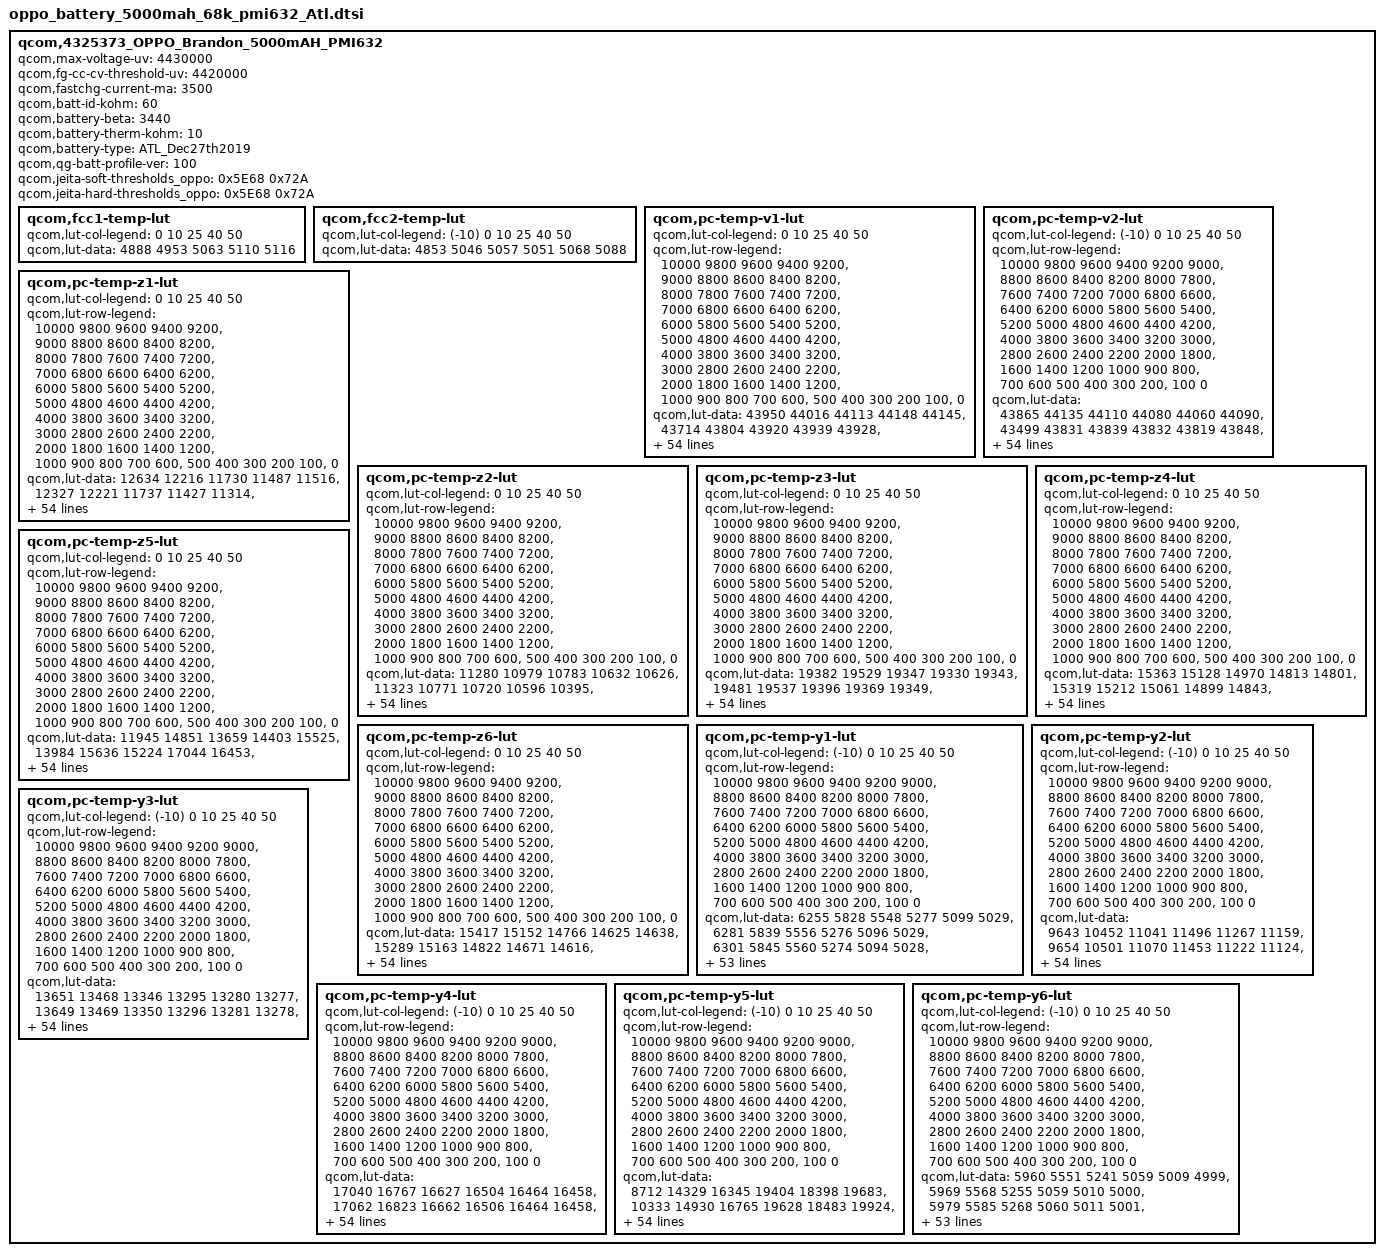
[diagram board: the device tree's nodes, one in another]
qcom,4325373_OPPO_Brandon_5000mAH_PMI632 {
    /* 4325373_OPPO_Brandon_5000mAH_PMI632_averaged_MasterSlave_Dec27th2019 */
    qcom,max-voltage-uv = <4430000>;
    qcom,fg-cc-cv-threshold-uv = <4420000>;
    qcom,fastchg-current-ma = <3500>;
    qcom,batt-id-kohm = <60>;
    qcom,battery-beta = <3440>;
    qcom,battery-therm-kohm = <10>;
    qcom,battery-type = "ATL_Dec27th2019";
    qcom,qg-batt-profile-ver = <100>;
    qcom,jeita-soft-thresholds_oppo = <0x5E68 0x72A>;
    qcom,jeita-hard-thresholds_oppo = <0x5E68 0x72A>;

	qcom,fcc1-temp-lut {
		qcom,lut-col-legend = <0 10 25 40 50>;
		qcom,lut-data = <4888 4953 5063 5110 5116>;
	};

	qcom,fcc2-temp-lut {
		qcom,lut-col-legend = <(-10) 0 10 25 40 50>;
		qcom,lut-data = <4853 5046 5057 5051 5068 5088>;
	};

	qcom,pc-temp-v1-lut {
		qcom,lut-col-legend = <0 10 25 40 50>;
		qcom,lut-row-legend = <10000 9800 9600 9400 9200>,
			<9000 8800 8600 8400 8200>,
			<8000 7800 7600 7400 7200>,
			<7000 6800 6600 6400 6200>,
			<6000 5800 5600 5400 5200>,
			<5000 4800 4600 4400 4200>,
			<4000 3800 3600 3400 3200>,
			<3000 2800 2600 2400 2200>,
			<2000 1800 1600 1400 1200>,
			<1000 900 800 700 600>,
			<500 400 300 200 100>,
			<0>;
		qcom,lut-data = <43950 44016 44113 44148 44145>,
			<43714 43804 43920 43939 43928>,
			<43479 43585 43722 43740 43733>,
			<43250 43361 43516 43537 43527>,
			<43023 43131 43290 43324 43313>,
			<42789 42897 43052 43103 43091>,
			<42550 42657 42813 42873 42861>,
			<42313 42418 42573 42635 42625>,
			<42082 42182 42333 42391 42384>,
			<41855 41947 42093 42151 42146>,
			<41630 41719 41855 41915 41913>,
			<41409 41495 41625 41682 41681>,
			<41194 41277 41402 41452 41453>,
			<40990 41069 41184 41227 41227>,
			<40791 40866 40970 41010 41008>,
			<40593 40666 40763 40802 40796>,
			<40401 40466 40564 40601 40592>,
			<40221 40276 40373 40409 40397>,
			<40057 40110 40188 40223 40211>,
			<39896 39959 40021 40047 40037>,
			<39713 39775 39850 39877 39873>,
			<39482 39524 39617 39673 39676>,
			<39260 39272 39312 39393 39405>,
			<39080 39077 39088 39146 39160>,
			<38926 38909 38964 39001 39014>,
			<38800 38787 38868 38891 38904>,
			<38684 38704 38770 38782 38791>,
			<38588 38636 38678 38676 38677>,
			<38511 38565 38590 38578 38571>,
			<38442 38496 38504 38483 38476>,
			<38376 38433 38424 38396 38389>,
			<38312 38373 38353 38320 38311>,
			<38256 38319 38290 38252 38240>,
			<38207 38271 38233 38187 38172>,
			<38164 38228 38185 38126 38104>,
			<38118 38188 38139 38066 38037>,
			<38058 38153 38092 38008 37969>,
			<38004 38115 38043 37953 37901>,
			<37976 38053 37978 37884 37821>,
			<37957 37955 37886 37789 37721>,
			<37917 37843 37777 37679 37608>,
			<37798 37719 37661 37562 37487>,
			<37643 37578 37526 37431 37352>,
			<37474 37410 37357 37271 37193>,
			<37342 37253 37204 37127 37058>,
			<37230 37153 37103 37039 36979>,
			<37188 37121 37074 37011 36950>,
			<37153 37095 37053 36991 36933>,
			<37125 37080 37031 36972 36911>,
			<37077 37032 36986 36911 36837>,
			<36914 36818 36751 36643 36547>,
			<36490 36378 36318 36201 36104>,
			<35919 35797 35745 35626 35528>,
			<35130 35000 34966 34841 34741>,
			<33816 33717 33765 33619 33516>,
			<30000 30000 30000 30000 30000>;
	};

	qcom,pc-temp-v2-lut {
		qcom,lut-col-legend = <(-10) 0 10 25 40 50>;
		qcom,lut-row-legend = <10000 9800 9600 9400 9200 9000>,
			<8800 8600 8400 8200 8000 7800>,
			<7600 7400 7200 7000 6800 6600>,
			<6400 6200 6000 5800 5600 5400>,
			<5200 5000 4800 4600 4400 4200>,
			<4000 3800 3600 3400 3200 3000>,
			<2800 2600 2400 2200 2000 1800>,
			<1600 1400 1200 1000 900 800>,
			<700 600 500 400 300 200>,
			<100 0>;
		qcom,lut-data = <43865 44135 44110 44080 44060 44090>,
			<43499 43831 43839 43832 43819 43848>,
			<43166 43548 43580 43591 43584 43614>,
			<42874 43290 43337 43357 43356 43386>,
			<42622 43056 43110 43133 43134 43168>,
			<42374 42822 42880 42905 42908 42944>,
			<42100 42578 42639 42667 42672 42710>,
			<41820 42333 42395 42426 42433 42471>,
			<41568 42090 42152 42186 42195 42233>,
			<41345 41850 41909 41948 41956 41993>,
			<41172 41606 41671 41713 41722 41757>,
			<41034 41335 41439 41483 41490 41525>,
			<40867 41080 41213 41258 41264 41297>,
			<40636 40908 40996 41038 41045 41074>,
			<40272 40786 40785 40823 40831 40856>,
			<39919 40630 40579 40616 40624 40647>,
			<39674 40369 40381 40416 40422 40446>,
			<39471 40067 40181 40223 40228 40253>,
			<39272 39810 39964 40041 40048 40073>,
			<39068 39573 39731 39867 39877 39899>,
			<38872 39342 39500 39668 39678 39697>,
			<38694 39114 39264 39408 39420 39448>,
			<38546 38896 39044 39151 39170 39209>,
			<38435 38692 38862 38961 38985 39020>,
			<38349 38497 38703 38803 38829 38857>,
			<38276 38351 38560 38666 38694 38717>,
			<38211 38236 38433 38545 38576 38596>,
			<38151 38145 38316 38437 38469 38488>,
			<38093 38081 38197 38337 38372 38387>,
			<38037 38030 38084 38243 38282 38293>,
			<37982 37983 38002 38158 38201 38208>,
			<37924 37939 37938 38080 38127 38131>,
			<37865 37895 37886 38007 38055 38057>,
			<37804 37846 37844 37939 37983 37985>,
			<37743 37795 37808 37874 37908 37909>,
			<37679 37741 37767 37804 37821 37813>,
			<37611 37684 37721 37730 37720 37694>,
			<37540 37620 37666 37652 37618 37581>,
			<37460 37546 37598 37574 37523 37484>,
			<37374 37462 37515 37493 37431 37390>,
			<37285 37367 37413 37405 37340 37299>,
			<37192 37257 37284 37309 37251 37207>,
			<37099 37133 37142 37192 37134 37086>,
			<37014 36992 36990 37050 36996 36948>,
			<36935 36846 36846 36920 36890 36835>,
			<36856 36754 36755 36865 36846 36798>,
			<36814 36723 36722 36846 36831 36787>,
			<36762 36698 36683 36829 36816 36771>,
			<36688 36658 36637 36794 36792 36740>,
			<36577 36599 36545 36731 36701 36643>,
			<36382 36433 36330 36490 36398 36310>,
			<36035 36015 35883 36018 35896 35810>,
			<35377 35356 35252 35400 35252 35158>,
			<34603 34363 34370 34554 34366 34257>,
			<33605 32848 32889 33221 32988 32849>,
			<30247 29719 28617 28832 28080 28127>;
	};

	qcom,pc-temp-z1-lut {
		qcom,lut-col-legend = <0 10 25 40 50>;
		qcom,lut-row-legend = <10000 9800 9600 9400 9200>,
			<9000 8800 8600 8400 8200>,
			<8000 7800 7600 7400 7200>,
			<7000 6800 6600 6400 6200>,
			<6000 5800 5600 5400 5200>,
			<5000 4800 4600 4400 4200>,
			<4000 3800 3600 3400 3200>,
			<3000 2800 2600 2400 2200>,
			<2000 1800 1600 1400 1200>,
			<1000 900 800 700 600>,
			<500 400 300 200 100>,
			<0>;
		qcom,lut-data = <12634 12216 11730 11487 11516>,
			<12327 12221 11737 11427 11314>,
			<12199 12222 11733 11424 11315>,
			<12193 12216 11727 11420 11313>,
			<12187 12202 11717 11415 11310>,
			<12177 12192 11702 11408 11307>,
			<12164 12184 11691 11401 11304>,
			<12153 12175 11683 11395 11302>,
			<12144 12163 11676 11391 11300>,
			<12135 12147 11669 11389 11299>,
			<12126 12134 11663 11387 11299>,
			<12119 12124 11658 11386 11299>,
			<12113 12117 11653 11385 11299>,
			<12108 12115 11651 11385 11299>,
			<12103 12114 11653 11385 11299>,
			<12095 12112 11656 11386 11300>,
			<12088 12112 11658 11387 11301>,
			<12089 12113 11659 11388 11303>,
			<12099 12113 11659 11389 11304>,
			<12107 12112 11660 11390 11306>,
			<12102 12112 11661 11392 11307>,
			<12090 12113 11663 11393 11308>,
			<12089 12115 11666 11394 11310>,
			<12104 12120 11669 11396 11312>,
			<12118 12131 11673 11398 11314>,
			<12118 12135 11677 11402 11317>,
			<12111 12134 11681 11406 11320>,
			<12109 12133 11685 11410 11323>,
			<12116 12136 11690 11414 11326>,
			<12125 12145 11695 11418 11330>,
			<12127 12151 11699 11422 11334>,
			<12125 12154 11703 11427 11338>,
			<12125 12157 11706 11431 11341>,
			<12126 12158 11711 11435 11344>,
			<12129 12161 11719 11439 11349>,
			<12143 12164 11727 11444 11353>,
			<12391 12169 11729 11448 11356>,
			<12682 12177 11732 11452 11360>,
			<12746 12190 11735 11457 11363>,
			<12777 12214 11743 11461 11366>,
			<12795 12225 11752 11466 11370>,
			<12799 12219 11761 11470 11373>,
			<12798 12213 11769 11474 11377>,
			<12817 12225 11775 11479 11380>,
			<12813 12241 11782 11486 11384>,
			<12831 12244 11792 11490 11386>,
			<12842 12234 11791 11491 11386>,
			<12829 12232 11795 11493 11387>,
			<12830 12249 11804 11495 11389>,
			<12836 12244 11804 11502 11393>,
			<12846 12253 11813 11508 11398>,
			<12845 12276 11828 11515 11404>,
			<12865 12294 11827 11525 11413>,
			<12893 12322 11859 11540 11427>,
			<12893 12322 11859 11540 11427>,
			<12893 12322 11859 11540 11427>;
	};

	qcom,pc-temp-z2-lut {
		qcom,lut-col-legend = <0 10 25 40 50>;
		qcom,lut-row-legend = <10000 9800 9600 9400 9200>,
			<9000 8800 8600 8400 8200>,
			<8000 7800 7600 7400 7200>,
			<7000 6800 6600 6400 6200>,
			<6000 5800 5600 5400 5200>,
			<5000 4800 4600 4400 4200>,
			<4000 3800 3600 3400 3200>,
			<3000 2800 2600 2400 2200>,
			<2000 1800 1600 1400 1200>,
			<1000 900 800 700 600>,
			<500 400 300 200 100>,
			<0>;
		qcom,lut-data = <11280 10979 10783 10632 10626>,
			<11323 10771 10720 10596 10395>,
			<11347 10646 11165 10622 10424>,
			<11232 10609 11499 10626 10509>,
			<11036 10570 11255 10686 10533>,
			<10831 10537 10771 11009 10501>,
			<10580 10507 10615 11198 10466>,
			<10455 10484 10582 10904 10442>,
			<10568 10467 10559 10499 10420>,
			<10745 10453 10537 10529 10395>,
			<10746 10450 10521 10892 10367>,
			<10583 10451 10557 11116 10335>,
			<10477 10455 10774 11174 10286>,
			<10584 10470 10942 11205 10243>,
			<10765 10503 10991 11194 10253>,
			<10840 10528 11022 11157 10300>,
			<10874 10544 10977 11142 10325>,
			<10908 10560 10751 11172 10338>,
			<10881 10581 10626 11200 10352>,
			<10736 10605 10633 11004 10362>,
			<10662 10624 10642 10557 10372>,
			<10633 10641 10666 10446 10386>,
			<10629 10652 10715 10544 10431>,
			<10612 10643 10738 10619 10476>,
			<10580 10615 10689 10578 10491>,
			<10574 10602 10630 10492 10514>,
			<10615 10602 10638 10494 10567>,
			<10653 10604 10683 10648 10728>,
			<10653 10607 10712 10753 10837>,
			<10642 10613 10723 10730 10736>,
			<10635 10620 10729 10682 10542>,
			<10632 10628 10724 10635 10417>,
			<10632 10636 10709 10576 10318>,
			<10641 10645 10703 10550 10278>,
			<10664 10653 10705 10561 10306>,
			<10674 10662 10710 10584 10356>,
			<10616 10670 10725 10612 10406>,
			<10551 10680 10757 10654 10464>,
			<10561 10693 10783 10694 10512>,
			<10605 10712 10803 10743 10553>,
			<10639 10726 10818 10779 10589>,
			<10655 10732 10825 10787 10617>,
			<10678 10741 10830 10790 10642>,
			<10738 10767 10844 10773 10690>,
			<10726 10941 10902 10750 10675>,
			<10580 11064 10944 10676 10571>,
			<10518 11071 10930 10664 10558>,
			<10463 11076 10903 10665 10579>,
			<10187 11441 10904 10683 10604>,
			<10491 11449 10973 10781 10672>,
			<10208 11419 11026 10654 10506>,
			<10095 11276 10973 10490 10321>,
			<9865 11099 10906 10443 10266>,
			<9689 10844 10893 10386 10202>,
			<9689 10844 10893 10386 10202>,
			<9689 10844 10893 10386 10202>;
	};

	qcom,pc-temp-z3-lut {
		qcom,lut-col-legend = <0 10 25 40 50>;
		qcom,lut-row-legend = <10000 9800 9600 9400 9200>,
			<9000 8800 8600 8400 8200>,
			<8000 7800 7600 7400 7200>,
			<7000 6800 6600 6400 6200>,
			<6000 5800 5600 5400 5200>,
			<5000 4800 4600 4400 4200>,
			<4000 3800 3600 3400 3200>,
			<3000 2800 2600 2400 2200>,
			<2000 1800 1600 1400 1200>,
			<1000 900 800 700 600>,
			<500 400 300 200 100>,
			<0>;
		qcom,lut-data = <19382 19529 19347 19330 19343>,
			<19481 19537 19396 19369 19349>,
			<19544 19546 19413 19387 19362>,
			<19582 19558 19425 19397 19378>,
			<19600 19572 19441 19406 19387>,
			<19606 19578 19456 19416 19392>,
			<19604 19581 19460 19421 19397>,
			<19601 19582 19459 19417 19401>,
			<19607 19580 19457 19412 19404>,
			<19616 19576 19457 19413 19403>,
			<19610 19571 19455 19420 19396>,
			<19589 19567 19455 19422 19389>,
			<19575 19563 19455 19418 19385>,
			<19574 19556 19454 19413 19381>,
			<19577 19547 19451 19407 19378>,
			<19579 19541 19447 19400 19376>,
			<19577 19538 19440 19394 19374>,
			<19574 19535 19426 19390 19370>,
			<19564 19528 19418 19386 19367>,
			<19550 19519 19417 19378 19361>,
			<19542 19518 19416 19366 19355>,
			<19542 19539 19419 19364 19352>,
			<19547 19560 19432 19368 19353>,
			<19552 19559 19439 19372 19353>,
			<19550 19552 19425 19364 19347>,
			<19546 19544 19409 19349 19334>,
			<19545 19537 19408 19348 19336>,
			<19544 19532 19410 19363 19375>,
			<19542 19531 19413 19379 19402>,
			<19542 19533 19427 19391 19400>,
			<19541 19535 19439 19401 19395>,
			<19540 19537 19440 19402 19389>,
			<19538 19538 19440 19395 19380>,
			<19534 19538 19440 19389 19371>,
			<19528 19536 19435 19383 19363>,
			<19525 19534 19429 19378 19357>,
			<19551 19531 19426 19373 19353>,
			<19588 19526 19424 19368 19351>,
			<19609 19522 19421 19365 19349>,
			<19625 19518 19418 19363 19346>,
			<19629 19514 19415 19362 19344>,
			<19621 19510 19411 19363 19347>,
			<19609 19504 19406 19364 19354>,
			<19589 19493 19404 19364 19359>,
			<19378 19462 19394 19360 19357>,
			<19289 19433 19382 19347 19340>,
			<19286 19427 19380 19344 19338>,
			<19283 19423 19377 19343 19328>,
			<19264 19319 19377 19336 19324>,
			<19278 19316 19363 19329 19323>,
			<19263 19322 19359 19352 19351>,
			<19264 19312 19370 19364 19358>,
			<19266 19310 19375 19362 19356>,
			<19272 19311 19357 19355 19354>,
			<19272 19311 19357 19355 19354>,
			<19272 19311 19357 19355 19354>;
	};

	qcom,pc-temp-z4-lut {
		qcom,lut-col-legend = <0 10 25 40 50>;
		qcom,lut-row-legend = <10000 9800 9600 9400 9200>,
			<9000 8800 8600 8400 8200>,
			<8000 7800 7600 7400 7200>,
			<7000 6800 6600 6400 6200>,
			<6000 5800 5600 5400 5200>,
			<5000 4800 4600 4400 4200>,
			<4000 3800 3600 3400 3200>,
			<3000 2800 2600 2400 2200>,
			<2000 1800 1600 1400 1200>,
			<1000 900 800 700 600>,
			<500 400 300 200 100>,
			<0>;
		qcom,lut-data = <15363 15128 14970 14813 14801>,
			<15319 15212 15061 14899 14843>,
			<15237 15232 15019 14893 14844>,
			<15129 15172 14964 14862 14825>,
			<15048 15070 14922 14829 14806>,
			<14992 14995 14882 14790 14786>,
			<14947 14939 14848 14764 14767>,
			<14910 14894 14819 14755 14749>,
			<14861 14859 14793 14747 14732>,
			<14813 14830 14770 14732 14720>,
			<14794 14806 14749 14699 14711>,
			<14790 14785 14729 14678 14704>,
			<14784 14768 14706 14672 14700>,
			<14764 14752 14691 14668 14696>,
			<14740 14739 14685 14665 14690>,
			<14727 14735 14680 14663 14685>,
			<14718 14735 14681 14660 14680>,
			<14707 14734 14693 14657 14675>,
			<14695 14730 14699 14654 14673>,
			<14696 14721 14697 14657 14672>,
			<14712 14719 14696 14669 14673>,
			<14749 14744 14715 14688 14679>,
			<14779 14779 14789 14752 14743>,
			<14793 14808 14829 14805 14800>,
			<14806 14836 14832 14812 14803>,
			<14813 14845 14833 14815 14803>,
			<14813 14834 14829 14812 14795>,
			<14804 14816 14810 14783 14742>,
			<14788 14802 14789 14750 14699>,
			<14768 14787 14764 14724 14690>,
			<14754 14774 14742 14703 14684>,
			<14742 14763 14731 14693 14681>,
			<14733 14754 14723 14687 14678>,
			<14727 14748 14720 14685 14677>,
			<14722 14745 14719 14686 14676>,
			<14720 14741 14718 14687 14677>,
			<14793 14737 14718 14689 14677>,
			<14877 14733 14719 14690 14678>,
			<14861 14732 14720 14692 14681>,
			<14777 14732 14725 14702 14692>,
			<14731 14731 14728 14710 14703>,
			<14726 14723 14721 14706 14698>,
			<14721 14712 14708 14696 14688>,
			<14715 14705 14702 14695 14687>,
			<14850 14683 14687 14688 14681>,
			<14913 14676 14666 14671 14666>,
			<14915 14675 14658 14665 14661>,
			<14915 14673 14648 14652 14655>,
			<14927 14782 14637 14640 14637>,
			<14910 14782 14646 14642 14632>,
			<14922 14780 14669 14648 14645>,
			<14938 14802 14663 14649 14650>,
			<14949 14809 14659 14654 14655>,
			<14968 14817 14683 14664 14660>,
			<14968 14817 14683 14664 14660>,
			<14968 14817 14683 14664 14660>;
	};

	qcom,pc-temp-z5-lut {
		qcom,lut-col-legend = <0 10 25 40 50>;
		qcom,lut-row-legend = <10000 9800 9600 9400 9200>,
			<9000 8800 8600 8400 8200>,
			<8000 7800 7600 7400 7200>,
			<7000 6800 6600 6400 6200>,
			<6000 5800 5600 5400 5200>,
			<5000 4800 4600 4400 4200>,
			<4000 3800 3600 3400 3200>,
			<3000 2800 2600 2400 2200>,
			<2000 1800 1600 1400 1200>,
			<1000 900 800 700 600>,
			<500 400 300 200 100>,
			<0>;
		qcom,lut-data = <11945 14851 13659 14403 15525>,
			<13984 15636 15224 17044 16453>,
			<15560 16298 15768 18124 17291>,
			<16791 16846 16164 18758 19113>,
			<17716 17517 17077 19495 20130>,
			<18238 18203 18350 20439 20754>,
			<18617 18924 19087 21008 21472>,
			<19115 19670 19530 21076 22983>,
			<21861 20408 20054 21140 24613>,
			<25425 21166 20982 22512 24885>,
			<25727 22011 22192 27328 24712>,
			<23578 22979 23573 30993 24654>,
			<22304 23993 26399 32938 24936>,
			<24172 25018 28597 34122 25482>,
			<27356 26058 29820 33821 26347>,
			<29658 27031 30935 32639 27861>,
			<31519 28129 30745 32224 29357>,
			<32410 28840 28024 33256 30970>,
			<31113 28652 26755 34357 32120>,
			<28413 28106 27635 32479 31695>,
			<28417 28893 29074 27768 30048>,
			<32974 44785 32092 26609 28410>,
			<37804 60858 38136 27228 26977>,
			<42160 58184 40771 27655 25269>,
			<42372 46674 33389 24650 21814>,
			<39670 38268 24164 18778 17261>,
			<37184 33124 22310 17465 16880>,
			<34845 29989 21661 18378 22317>,
			<32702 29890 21589 19800 26931>,
			<31704 30465 24412 23063 28469>,
			<32307 31366 28687 27294 29511>,
			<33589 33800 32282 29123 29641>,
			<34812 36951 35832 30062 28891>,
			<35394 39471 37804 30968 28497>,
			<35834 41872 38823 32331 28585>,
			<35933 42804 39409 33432 28745>,
			<33140 42524 39584 33192 28981>,
			<30032 42024 39541 31896 29253>,
			<31748 41551 39113 30585 29041>,
			<37693 41024 36797 28758 26588>,
			<40452 40417 34086 27110 24183>,
			<38968 39385 32053 26531 24559>,
			<36883 37946 30707 26210 26081>,
			<34864 35086 30675 26053 28290>,
			<19093 35666 30941 26145 28666>,
			<12486 30485 31479 23454 23003>,
			<12365 27295 31471 23061 22195>,
			<12263 26561 31590 25194 20679>,
			<11900 13457 34347 25746 24095>,
			<12104 13365 26391 22599 24367>,
			<11936 13663 21085 25931 29236>,
			<11854 13029 21833 26048 26618>,
			<11756 12820 22156 23083 22620>,
			<11812 12679 18207 18814 18982>,
			<11812 12679 18207 18814 18982>,
			<11812 12679 18207 18814 18982>;
	};

	qcom,pc-temp-z6-lut {
		qcom,lut-col-legend = <0 10 25 40 50>;
		qcom,lut-row-legend = <10000 9800 9600 9400 9200>,
			<9000 8800 8600 8400 8200>,
			<8000 7800 7600 7400 7200>,
			<7000 6800 6600 6400 6200>,
			<6000 5800 5600 5400 5200>,
			<5000 4800 4600 4400 4200>,
			<4000 3800 3600 3400 3200>,
			<3000 2800 2600 2400 2200>,
			<2000 1800 1600 1400 1200>,
			<1000 900 800 700 600>,
			<500 400 300 200 100>,
			<0>;
		qcom,lut-data = <15417 15152 14766 14625 14638>,
			<15289 15163 14822 14671 14616>,
			<15207 15165 14810 14672 14622>,
			<15158 15139 14793 14665 14623>,
			<15119 15081 14780 14658 14622>,
			<15084 15036 14765 14647 14616>,
			<15051 15003 14751 14637 14609>,
			<15023 14973 14735 14630 14604>,
			<14997 14948 14720 14623 14599>,
			<14974 14925 14707 14615 14592>,
			<14953 14906 14695 14606 14584>,
			<14936 14890 14685 14599 14578>,
			<14921 14876 14675 14594 14573>,
			<14908 14863 14668 14589 14569>,
			<14897 14851 14663 14584 14565>,
			<14888 14845 14659 14579 14562>,
			<14879 14842 14656 14575 14558>,
			<14870 14839 14653 14571 14554>,
			<14860 14834 14652 14568 14551>,
			<14853 14826 14651 14566 14548>,
			<14853 14825 14650 14565 14544>,
			<14870 14848 14660 14567 14546>,
			<14886 14875 14701 14599 14574>,
			<14896 14888 14721 14625 14599>,
			<14903 14897 14717 14624 14598>,
			<14904 14900 14710 14619 14593>,
			<14904 14892 14705 14616 14590>,
			<14902 14883 14700 14612 14587>,
			<14896 14878 14696 14609 14585>,
			<14888 14875 14694 14605 14581>,
			<14883 14872 14691 14602 14577>,
			<14878 14869 14689 14598 14572>,
			<14874 14868 14687 14593 14567>,
			<14870 14867 14685 14589 14562>,
			<14866 14866 14683 14587 14558>,
			<14870 14865 14681 14585 14555>,
			<14994 14865 14681 14584 14554>,
			<15137 14864 14681 14582 14553>,
			<15148 14865 14681 14581 14553>,
			<15132 14867 14683 14585 14557>,
			<15125 14869 14685 14589 14561>,
			<15128 14868 14682 14588 14561>,
			<15130 14866 14677 14585 14561>,
			<15129 14864 14676 14585 14562>,
			<15102 14851 14669 14581 14560>,
			<15086 14837 14657 14568 14545>,
			<15087 14834 14653 14564 14542>,
			<15086 14832 14648 14558 14534>,
			<15084 14828 14644 14549 14524>,
			<15088 14831 14644 14547 14522>,
			<15096 14839 14654 14564 14543>,
			<15113 14850 14661 14573 14552>,
			<15130 14860 14666 14576 14556>,
			<15159 14876 14672 14580 14560>,
			<15159 14876 14672 14580 14560>,
			<15159 14876 14672 14580 14560>;
	};

	qcom,pc-temp-y1-lut {
		qcom,lut-col-legend = <(-10) 0 10 25 40 50>;
		qcom,lut-row-legend = <10000 9800 9600 9400 9200 9000>,
			<8800 8600 8400 8200 8000 7800>,
			<7600 7400 7200 7000 6800 6600>,
			<6400 6200 6000 5800 5600 5400>,
			<5200 5000 4800 4600 4400 4200>,
			<4000 3800 3600 3400 3200 3000>,
			<2800 2600 2400 2200 2000 1800>,
			<1600 1400 1200 1000 900 800>,
			<700 600 500 400 300 200>,
			<100 0>;
		qcom,lut-data = <6255 5828 5548 5277 5099 5029>,
			<6281 5839 5556 5276 5096 5029>,
			<6301 5845 5560 5274 5094 5028>,
			<6315 5848 5560 5270 5091 5028>,
			<6324 5849 5559 5266 5089 5027>,
			<6327 5849 5557 5264 5087 5026>,
			<6327 5852 5552 5261 5085 5026>,
			<6317 5856 5547 5259 5084 5025>,
			<6309 5856 5546 5257 5083 5025>,
			<6314 5855 5548 5254 5083 5025>,
			<6323 5854 5548 5253 5082 5024>,
			<6333 5854 5547 5254 5081 5024>,
			<6341 5853 5546 5256 5080 5023>,
			<6338 5853 5545 5255 5080 5023>,
			<6334 5854 5541 5253 5080 5023>,
			<6340 5856 5540 5251 5080 5023>,
			<6346 5856 5543 5253 5081 5024>,
			<6344 5857 5547 5256 5081 5026>,
			<6342 5862 5549 5258 5082 5026>,
			<6346 5874 5552 5259 5083 5027>,
			<6347 5880 5554 5261 5084 5027>,
			<6337 5875 5556 5262 5086 5028>,
			<6329 5870 5558 5263 5088 5028>,
			<6331 5869 5560 5266 5089 5029>,
			<6333 5867 5562 5271 5091 5032>,
			<6333 5867 5562 5275 5092 5033>,
			<6331 5873 5560 5277 5095 5035>,
			<6328 5878 5559 5280 5097 5037>,
			<6325 5879 5564 5285 5100 5038>,
			<6337 5882 5572 5290 5102 5041>,
			<6348 5886 5574 5293 5104 5043>,
			<6347 5893 5573 5296 5108 5046>,
			<6344 5898 5573 5298 5111 5048>,
			<6348 5892 5572 5300 5114 5050>,
			<6348 5877 5571 5302 5116 5052>,
			<6344 5873 5571 5305 5119 5053>,
			<6347 5882 5578 5313 5121 5055>,
			<6354 5889 5583 5318 5123 5056>,
			<6355 5888 5585 5318 5125 5058>,
			<6350 5884 5588 5316 5126 5060>,
			<6350 5886 5592 5316 5128 5061>,
			<6354 5900 5597 5320 5130 5063>,
			<6359 5907 5599 5327 5133 5065>,
			<6348 5914 5605 5342 5135 5066>,
			<6343 5910 5605 5346 5139 5070>,
			<6361 5918 5599 5344 5141 5071>,
			<6408 5949 5601 5355 5143 5072>,
			<6409 5947 5619 5353 5142 5072>,
			<6443 5939 5612 5349 5142 5072>,
			<6516 5947 5622 5353 5142 5073>,
			<6566 5986 5640 5357 5142 5074>,
			<6679 6015 5655 5368 5148 5079>,
			<6722 6089 5681 5371 5155 5085>,
			<6517 6200 5757 5392 5165 5094>,
			<6517 6200 5757 5392 5165 5094>,
			<6517 6200 5757 5392 5165 5094>;
	};

	qcom,pc-temp-y2-lut {
		qcom,lut-col-legend = <(-10) 0 10 25 40 50>;
		qcom,lut-row-legend = <10000 9800 9600 9400 9200 9000>,
			<8800 8600 8400 8200 8000 7800>,
			<7600 7400 7200 7000 6800 6600>,
			<6400 6200 6000 5800 5600 5400>,
			<5200 5000 4800 4600 4400 4200>,
			<4000 3800 3600 3400 3200 3000>,
			<2800 2600 2400 2200 2000 1800>,
			<1600 1400 1200 1000 900 800>,
			<700 600 500 400 300 200>,
			<100 0>;
		qcom,lut-data = <9643 10452 11041 11496 11267 11159>,
			<9654 10501 11070 11453 11222 11124>,
			<9966 10564 11094 11412 11166 11087>,
			<10200 10629 11112 11374 11110 11052>,
			<10351 10682 11121 11339 11063 11020>,
			<10415 10711 11119 11308 11036 10992>,
			<10352 10722 11105 11280 11024 10968>,
			<10263 10729 11087 11255 11016 10946>,
			<10262 10734 11071 11235 11009 10923>,
			<10254 10728 11056 11217 11004 10901>,
			<10245 10725 11048 11210 10997 10890>,
			<10249 10801 11046 11212 10980 10891>,
			<10289 10897 11044 11216 10965 10893>,
			<10325 10916 11066 11222 10980 10889>,
			<10204 10937 11151 11231 11034 10883>,
			<9869 10970 11230 11247 11076 10886>,
			<9696 11046 11293 11294 11096 10923>,
			<9690 11125 11344 11363 11119 10979>,
			<9686 11154 11374 11439 11206 11050>,
			<9682 11171 11396 11528 11369 11134>,
			<9679 11166 11402 11558 11422 11157>,
			<9676 10871 11395 11525 11353 11150>,
			<9674 10540 11388 11490 11281 11144>,
			<9673 10474 11396 11495 11261 11163>,
			<9671 10408 11419 11518 11248 11197>,
			<9670 10321 11433 11541 11248 11221>,
			<9669 10069 11428 11564 11287 11264>,
			<9668 9819 11415 11589 11341 11303>,
			<9667 9749 11394 11619 11396 11319>,
			<9667 9711 11359 11652 11460 11331>,
			<9666 9695 11329 11670 11510 11350>,
			<9666 9687 11298 11687 11570 11393>,
			<9665 9682 11263 11697 11612 11441>,
			<9665 9677 11220 11697 11634 11520>,
			<9664 9673 11154 11693 11657 11595>,
			<9664 9670 11038 11681 11648 11573>,
			<9664 9668 10773 11654 11567 11459>,
			<9663 9666 10549 11620 11498 11380>,
			<9663 9664 10434 11581 11468 11355>,
			<9663 9663 10331 11535 11448 11349>,
			<9663 9662 10196 11492 11454 11353>,
			<9662 9661 9904 11451 11484 11330>,
			<9662 9661 9750 11395 11451 11251>,
			<9661 9660 9695 11316 11337 11206>,
			<9660 9660 9681 11247 11273 11186>,
			<9658 9659 9678 11246 11197 10995>,
			<9657 9658 9673 11227 11175 10995>,
			<9655 9658 9669 11215 11174 11079>,
			<9653 9657 9665 11187 11256 11090>,
			<9651 9656 9662 11195 11278 11004>,
			<9649 9654 9660 11133 11157 10965>,
			<9648 9651 9657 11014 11051 10900>,
			<9648 9649 9655 10893 11016 10806>,
			<9648 9648 9652 10768 10879 10650>,
			<9648 9648 9652 10768 10879 10650>,
			<9648 9648 9652 10768 10879 10650>;
	};

	qcom,pc-temp-y3-lut {
		qcom,lut-col-legend = <(-10) 0 10 25 40 50>;
		qcom,lut-row-legend = <10000 9800 9600 9400 9200 9000>,
			<8800 8600 8400 8200 8000 7800>,
			<7600 7400 7200 7000 6800 6600>,
			<6400 6200 6000 5800 5600 5400>,
			<5200 5000 4800 4600 4400 4200>,
			<4000 3800 3600 3400 3200 3000>,
			<2800 2600 2400 2200 2000 1800>,
			<1600 1400 1200 1000 900 800>,
			<700 600 500 400 300 200>,
			<100 0>;
		qcom,lut-data = <13651 13468 13346 13295 13280 13277>,
			<13649 13469 13350 13296 13281 13278>,
			<13633 13470 13354 13298 13281 13279>,
			<13614 13471 13358 13299 13282 13280>,
			<13597 13472 13361 13300 13283 13281>,
			<13592 13474 13364 13300 13284 13282>,
			<13596 13476 13365 13301 13284 13282>,
			<13599 13478 13367 13301 13285 13283>,
			<13597 13479 13368 13301 13285 13283>,
			<13569 13479 13369 13302 13286 13284>,
			<13542 13476 13370 13303 13286 13284>,
			<13544 13447 13372 13304 13287 13284>,
			<13557 13413 13374 13306 13287 13285>,
			<13561 13412 13370 13306 13288 13285>,
			<13547 13426 13356 13307 13291 13285>,
			<13525 13433 13349 13307 13293 13286>,
			<13513 13427 13351 13307 13293 13288>,
			<13510 13417 13353 13307 13292 13290>,
			<13511 13407 13352 13307 13293 13291>,
			<13511 13394 13347 13306 13295 13292>,
			<13507 13387 13342 13306 13295 13292>,
			<13505 13382 13336 13302 13290 13287>,
			<13505 13378 13331 13298 13284 13282>,
			<13508 13373 13328 13296 13282 13280>,
			<13519 13363 13326 13294 13281 13279>,
			<13540 13358 13324 13293 13280 13279>,
			<13565 13358 13321 13293 13280 13279>,
			<13594 13361 13319 13293 13280 13279>,
			<13623 13371 13317 13293 13280 13278>,
			<13652 13387 13315 13292 13280 13277>,
			<13682 13405 13314 13292 13280 13277>,
			<13714 13431 13314 13292 13281 13277>,
			<13746 13462 13315 13292 13281 13277>,
			<13781 13494 13317 13292 13281 13278>,
			<13819 13530 13321 13292 13281 13280>,
			<13858 13572 13325 13292 13281 13279>,
			<13897 13625 13329 13292 13281 13278>,
			<13936 13683 13335 13291 13280 13278>,
			<13973 13744 13344 13291 13280 13278>,
			<14008 13808 13357 13291 13280 13279>,
			<14042 13866 13371 13291 13280 13280>,
			<14073 13920 13387 13294 13283 13281>,
			<14109 13968 13410 13295 13282 13281>,
			<14161 14009 13445 13296 13280 13279>,
			<14238 14050 13483 13297 13280 13276>,
			<14385 14086 13507 13298 13283 13283>,
			<14588 14150 13549 13301 13286 13287>,
			<14918 14234 13607 13306 13291 13289>,
			<15753 14325 13690 13309 13294 13290>,
			<17793 14490 13794 13316 13293 13288>,
			<22243 14829 13936 13313 13288 13284>,
			<37417 16283 14169 13313 13287 13285>,
			<65535 21599 14535 13320 13292 13288>,
			<65535 45812 15697 13332 13298 13294>,
			<65535 45812 15697 13332 13298 13294>,
			<65535 45812 15697 13332 13298 13294>;
	};

	qcom,pc-temp-y4-lut {
		qcom,lut-col-legend = <(-10) 0 10 25 40 50>;
		qcom,lut-row-legend = <10000 9800 9600 9400 9200 9000>,
			<8800 8600 8400 8200 8000 7800>,
			<7600 7400 7200 7000 6800 6600>,
			<6400 6200 6000 5800 5600 5400>,
			<5200 5000 4800 4600 4400 4200>,
			<4000 3800 3600 3400 3200 3000>,
			<2800 2600 2400 2200 2000 1800>,
			<1600 1400 1200 1000 900 800>,
			<700 600 500 400 300 200>,
			<100 0>;
		qcom,lut-data = <17040 16767 16627 16504 16464 16458>,
			<17062 16823 16662 16506 16464 16458>,
			<17091 16903 16706 16508 16464 16458>,
			<17121 16986 16750 16509 16464 16458>,
			<17146 17050 16783 16510 16464 16458>,
			<17159 17075 16795 16511 16465 16458>,
			<17162 17068 16791 16511 16466 16458>,
			<17161 17056 16783 16511 16467 16458>,
			<17163 17047 16775 16512 16468 16458>,
			<17218 17036 16768 16514 16470 16461>,
			<17300 17031 16762 16517 16473 16463>,
			<17338 17067 16759 16520 16477 16465>,
			<17308 17119 16759 16525 16482 16468>,
			<17233 17149 16779 16531 16485 16472>,
			<17114 17196 16838 16540 16487 16477>,
			<17019 17215 16864 16551 16491 16482>,
			<16988 17138 16862 16568 16500 16486>,
			<16955 17026 16858 16588 16513 16491>,
			<16908 16964 16843 16613 16533 16504>,
			<16853 16917 16803 16644 16560 16525>,
			<16803 16869 16758 16652 16567 16530>,
			<16770 16813 16703 16597 16532 16512>,
			<16754 16759 16653 16532 16494 16491>,
			<16754 16705 16626 16509 16478 16475>,
			<16758 16651 16606 16496 16468 16462>,
			<16760 16630 16591 16492 16466 16460>,
			<16760 16628 16580 16493 16468 16460>,
			<16757 16628 16568 16494 16471 16462>,
			<16755 16633 16546 16497 16476 16467>,
			<16755 16646 16520 16502 16483 16475>,
			<16756 16655 16511 16507 16492 16483>,
			<16761 16660 16513 16514 16503 16492>,
			<16768 16666 16519 16519 16510 16499>,
			<16774 16675 16530 16519 16513 16506>,
			<16777 16686 16549 16518 16514 16510>,
			<16779 16696 16570 16516 16512 16506>,
			<16781 16706 16596 16502 16495 16488>,
			<16782 16713 16618 16491 16480 16477>,
			<16781 16715 16633 16490 16473 16473>,
			<16775 16716 16645 16491 16468 16471>,
			<16770 16715 16652 16493 16469 16473>,
			<16767 16711 16657 16505 16473 16478>,
			<16766 16705 16660 16514 16472 16475>,
			<16771 16692 16661 16517 16461 16460>,
			<16785 16683 16654 16513 16452 16444>,
			<16802 16669 16644 16505 16460 16457>,
			<16830 16676 16660 16516 16477 16483>,
			<16879 16686 16681 16534 16506 16515>,
			<17013 16709 16713 16560 16539 16547>,
			<17349 16737 16762 16594 16544 16552>,
			<18117 16748 16791 16569 16489 16479>,
			<22148 16901 16790 16550 16471 16468>,
			<37061 18043 16803 16572 16476 16469>,
			<38496 31657 17162 16609 16493 16480>,
			<38496 31657 17162 16609 16493 16480>,
			<38496 31657 17162 16609 16493 16480>;
	};

	qcom,pc-temp-y5-lut {
		qcom,lut-col-legend = <(-10) 0 10 25 40 50>;
		qcom,lut-row-legend = <10000 9800 9600 9400 9200 9000>,
			<8800 8600 8400 8200 8000 7800>,
			<7600 7400 7200 7000 6800 6600>,
			<6400 6200 6000 5800 5600 5400>,
			<5200 5000 4800 4600 4400 4200>,
			<4000 3800 3600 3400 3200 3000>,
			<2800 2600 2400 2200 2000 1800>,
			<1600 1400 1200 1000 900 800>,
			<700 600 500 400 300 200>,
			<100 0>;
		qcom,lut-data = <8712 14329 16345 19404 18398 19683>,
			<10333 14930 16765 19628 18483 19924>,
			<12644 15521 17168 19582 18446 20027>,
			<14583 16096 17543 19351 18311 20029>,
			<15994 16649 17877 19019 18100 19964>,
			<16719 17174 18159 18672 17837 19868>,
			<16650 17723 18438 18165 17467 19714>,
			<16256 18211 18644 17597 17048 19471>,
			<16050 18502 18640 17240 16717 19043>,
			<15857 18656 18505 16895 16439 18286>,
			<15783 18493 18365 16653 16140 17638>,
			<17211 16690 18368 16545 15704 17185>,
			<20705 14580 18355 16467 15359 16763>,
			<22355 15284 17716 16256 15511 16229>,
			<20513 18815 16097 15793 16093 15648>,
			<17139 20730 15426 15473 16318 15493>,
			<15773 20899 16750 15213 15648 15845>,
			<15847 21016 18748 15002 14936 16176>,
			<15937 21366 20259 15381 15043 16146>,
			<15858 22029 21706 16878 15612 16042>,
			<15399 22441 22497 18543 16426 16163>,
			<14347 22454 22858 20667 18189 17714>,
			<13087 22290 23100 22354 19569 19179>,
			<12536 21501 23346 22564 19500 19516>,
			<12337 19676 23680 22329 19137 19713>,
			<12273 18819 23968 22154 18694 19667>,
			<12330 16146 24419 22061 17979 19184>,
			<12475 13320 24772 21974 17495 18494>,
			<12670 12919 24183 21873 17480 17370>,
			<12869 12861 22795 21783 17486 16201>,
			<12985 12963 22014 21880 17531 16012>,
			<12998 13336 20479 22270 17807 16124>,
			<12974 13704 19123 22830 18217 16349>,
			<13012 13850 18929 23762 18869 17485>,
			<13120 13963 18932 24919 19775 19042>,
			<13258 14096 18860 25158 20617 19750>,
			<13412 14364 18533 24565 21531 20121>,
			<13528 14592 18327 23653 21976 20565>,
			<13560 14689 18215 22177 21257 21334>,
			<13552 14765 17961 20341 20194 22114>,
			<13508 14752 17445 19567 20397 22474>,
			<13298 14579 16182 19298 21777 22721>,
			<13020 14437 15240 18873 21538 23013>,
			<12870 14330 14698 18253 20142 22548>,
			<12841 13533 14561 18552 19474 18141>,
			<12917 13467 14558 19600 18329 19829>,
			<12828 13535 14452 18861 18103 19048>,
			<12653 13882 14320 18984 18326 17822>,
			<12367 13513 14712 18247 18517 16961>,
			<11887 13751 14687 18996 18117 16448>,
			<10845 13805 14567 18989 17623 17019>,
			<9865 12044 14090 19301 18394 17558>,
			<9230 10037 13615 19158 19712 17818>,
			<9010 9005 11714 19221 23147 21361>,
			<9010 9005 11714 19221 23147 21361>,
			<9010 9005 11714 19221 23147 21361>;
	};

	qcom,pc-temp-y6-lut {
		qcom,lut-col-legend = <(-10) 0 10 25 40 50>;
		qcom,lut-row-legend = <10000 9800 9600 9400 9200 9000>,
			<8800 8600 8400 8200 8000 7800>,
			<7600 7400 7200 7000 6800 6600>,
			<6400 6200 6000 5800 5600 5400>,
			<5200 5000 4800 4600 4400 4200>,
			<4000 3800 3600 3400 3200 3000>,
			<2800 2600 2400 2200 2000 1800>,
			<1600 1400 1200 1000 900 800>,
			<700 600 500 400 300 200>,
			<100 0>;
		qcom,lut-data = <5960 5551 5241 5059 5009 4999>,
			<5969 5568 5255 5059 5010 5000>,
			<5979 5585 5268 5060 5011 5001>,
			<5989 5599 5278 5061 5011 5002>,
			<5996 5609 5285 5061 5012 5002>,
			<5999 5613 5287 5061 5012 5003>,
			<5990 5610 5285 5061 5013 5003>,
			<5970 5605 5280 5061 5013 5004>,
			<5956 5600 5275 5061 5014 5004>,
			<5954 5595 5271 5062 5015 5005>,
			<5962 5589 5268 5063 5016 5006>,
			<5977 5579 5267 5065 5017 5007>,
			<5987 5571 5266 5067 5019 5008>,
			<5972 5577 5268 5069 5021 5010>,
			<5923 5604 5274 5072 5023 5011>,
			<5878 5617 5277 5075 5026 5013>,
			<5862 5596 5277 5080 5029 5015>,
			<5855 5564 5277 5086 5032 5018>,
			<5847 5545 5273 5093 5038 5024>,
			<5836 5530 5259 5101 5047 5030>,
			<5828 5516 5243 5103 5049 5031>,
			<5824 5501 5225 5085 5035 5022>,
			<5826 5488 5209 5064 5020 5012>,
			<5835 5477 5202 5056 5014 5006>,
			<5853 5468 5197 5052 5010 5001>,
			<5874 5466 5194 5051 5009 5001>,
			<5894 5476 5192 5051 5010 5001>,
			<5916 5491 5191 5052 5011 5002>,
			<5940 5510 5188 5054 5012 5003>,
			<5965 5540 5185 5056 5015 5005>,
			<5992 5572 5184 5058 5018 5007>,
			<6020 5606 5192 5061 5021 5010>,
			<6049 5643 5203 5064 5024 5012>,
			<6079 5684 5217 5065 5026 5015>,
			<6111 5729 5236 5066 5027 5017>,
			<6143 5778 5257 5066 5026 5016>,
			<6176 5833 5282 5063 5021 5010>,
			<6208 5890 5310 5061 5017 5007>,
			<6239 5947 5342 5061 5015 5007>,
			<6269 6003 5377 5062 5013 5007>,
			<6299 6054 5413 5065 5014 5008>,
			<6327 6100 5452 5073 5018 5011>,
			<6360 6141 5496 5079 5017 5010>,
			<6408 6176 5547 5084 5013 5004>,
			<6486 6213 5599 5087 5011 4998>,
			<6634 6246 5630 5087 5016 5008>,
			<6830 6301 5685 5094 5023 5017>,
			<7144 6375 5755 5105 5034 5028>,
			<7864 6462 5846 5116 5046 5038>,
			<9524 6615 5960 5131 5047 5039>,
			<12955 6914 6101 5123 5028 5015>,
			<24456 8151 6309 5123 5023 5013>,
			<65535 12372 6632 5147 5029 5017>,
			<65535 32825 7689 5184 5040 5026>,
			<65535 32825 7689 5184 5040 5026>,
			<65535 32825 7689 5184 5040 5026>;
	};

};
